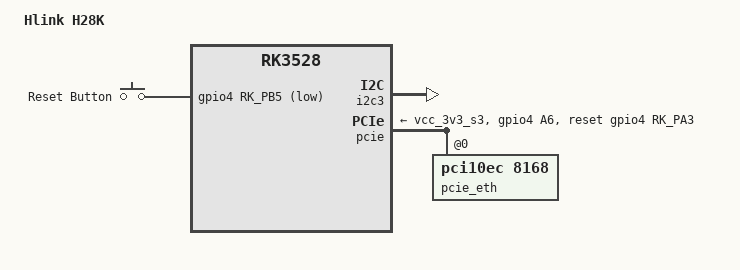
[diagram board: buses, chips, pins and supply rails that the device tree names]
// SPDX-License-Identifier: (GPL-2.0+ OR MIT)
/*
 * Copyright (c) 2022 Rockchip Electronics Co., Ltd.
 * Copyright (c) 2025 flippy <flippy@sina.com>
 */

#include "rk3528-hlink.dtsi"

/ {
	model = "Hlink H28K";
	compatible = "hlink,h28k", "rockchip,rk3528";

	aliases {
		ethernet1 = &pcie_eth;
	};

	gpio_keys: gpio-keys {
		compatible = "gpio-keys";
		status = "okay";

		key-factory {
			debounce-interval = <100>;
			gpios = <&gpio4 RK_PB5 GPIO_ACTIVE_LOW>;
			label = "Reset Button";
			linux,code = <KEY_RESTART>;
		};
	};
};

&i2c3 {
	status = "okay";
};

&pcie {
	status = "okay";
	reset-gpios = <&gpio4 RK_PA3 GPIO_ACTIVE_HIGH>;
	vpcie3v3-supply = <&vcc_3v3_s3>;

	pinctrl-names = "default";
	pinctrl-0 = <&pcie_rtl8111_isolate>;

	pcie@0,0 {
		reg = <0x000000 0 0 0 0>;
		#address-cells = <3>;
		#size-cells = <2>;

		bus-range = <0x00 0x0f>;
		device_type = "pci";
		ranges;

		pcie_eth: pcie-eth@0,0 {
			compatible = "pci10ec,8168";
			reg = <0x000000 0 0 0 0>;
			realtek,led-data = <0x0870>;
		};
	};
};

&pinctrl {
	pcie {
		pcie_rtl8111_isolate: pcie-rtl8111-isolate {
			rockchip,pins = <4 RK_PA6 RK_FUNC_GPIO &pcfg_pull_up>;
		};
	};
};
